AUTOSAR XML (schema 4-2-2)
package /STELLANTIS/EPT/ASWCs
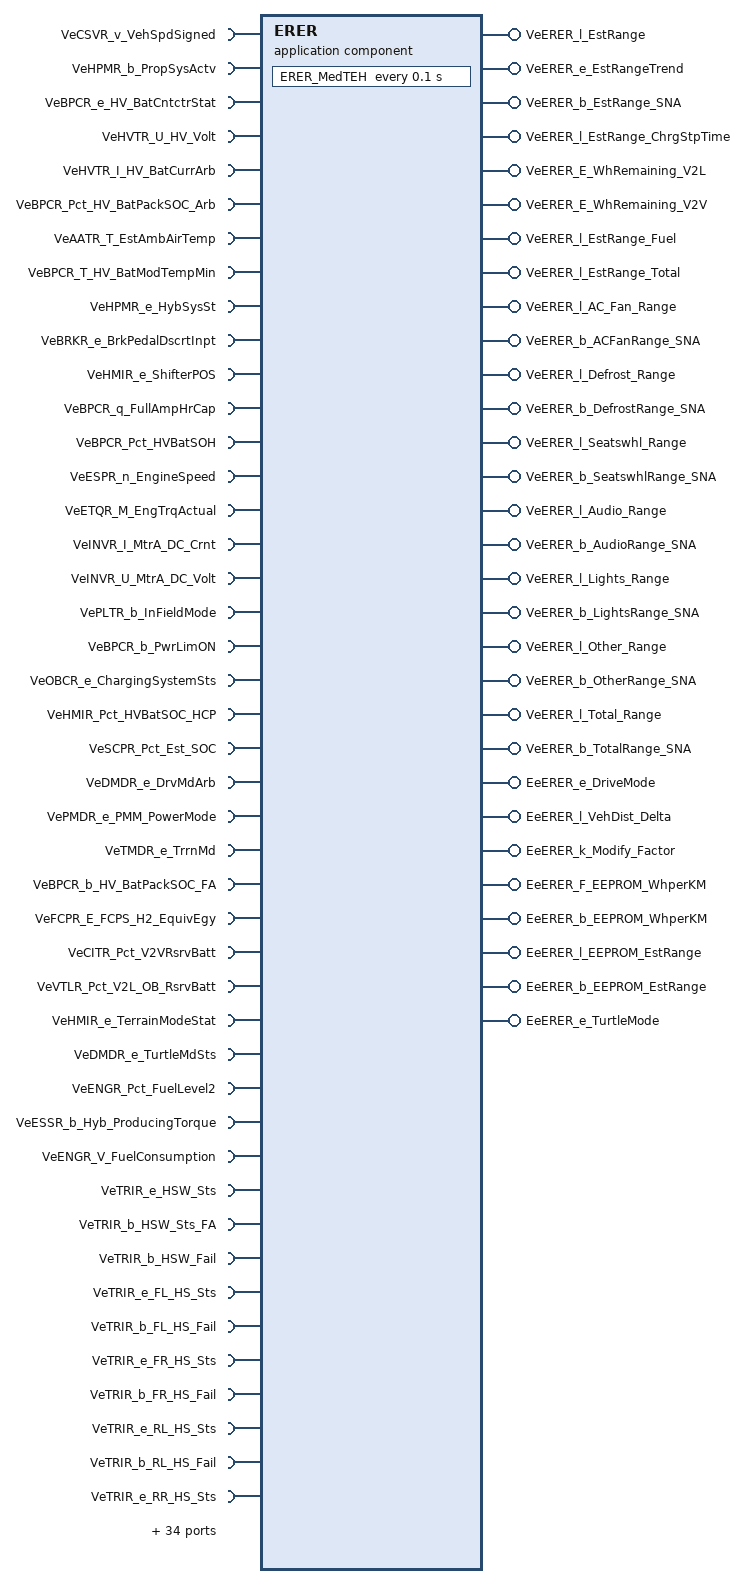
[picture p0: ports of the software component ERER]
  application sw component type ERER
    70 x require port:
      VeCSVR_v_VehSpdSigned: variation-point={short-label=vpVeCSVR_v_VehSpdSigned, sw-syscond=1}, nonqueued-receiver-com-spec{data-element=Value, init-value=0}, required-interface=VeCSVR_v_VehSpdSigned
      VeHPMR_b_PropSysActv: variation-point={short-label=vpVeHPMR_b_PropSysActv, sw-syscond=1}, nonqueued-receiver-com-spec{data-element=Value, init-value=0}, required-interface=VeHPMR_b_PropSysActv
      VeBPCR_e_HV_BatCntctrStat: variation-point={short-label=vpVeBPCR_e_HV_BatCntctrStat, sw-syscond=1}, nonqueued-receiver-com-spec{data-element=Value, init-value=CeHVTR_e_Open}, required-interface=VeBPCR_e_HV_BatCntctrStat
      VeHVTR_U_HV_Volt: variation-point={short-label=vpVeHVTR_U_HV_Volt, sw-syscond=1}, nonqueued-receiver-com-spec{data-element=Value, init-value=0}, required-interface=VeHVTR_U_HV_Volt
      VeHVTR_I_HV_BatCurrArb: variation-point={short-label=vpVeHVTR_I_HV_BatCurrArb, sw-syscond=1}, nonqueued-receiver-com-spec{data-element=Value, init-value=0}, required-interface=VeHVTR_I_HV_BatCurrArb
      VeBPCR_Pct_HV_BatPackSOC_Arb: variation-point={short-label=vpVeBPCR_Pct_HV_BatPackSOC_Arb, sw-syscond=1}, nonqueued-receiver-com-spec{data-element=Value, init-value=0}, required-interface=VeBPCR_Pct_HV_BatPackSOC_Arb
      VeAATR_T_EstAmbAirTemp: variation-point={short-label=vpVeAATR_T_EstAmbAirTemp, sw-syscond=1}, nonqueued-receiver-com-spec{data-element=Value, init-value=0}, required-interface=VeAATR_T_EstAmbAirTemp
      VeBPCR_T_HV_BatModTempMin: variation-point={short-label=vpVeBPCR_T_HV_BatModTempMin, sw-syscond=1}, nonqueued-receiver-com-spec{data-element=Value, init-value=0}, required-interface=VeBPCR_T_HV_BatModTempMin
      VeHPMR_e_HybSysSt: variation-point={short-label=vpVeHPMR_e_HybSysSt, sw-syscond=1}, nonqueued-receiver-com-spec{data-element=Value, init-value=CeHPMR_e_POWERUP}, required-interface=VeHPMR_e_HybSysSt
      VeBRKR_e_BrkPedalDscrtInpt: variation-point={short-label=vpVeBRKR_e_BrkPedalDscrtInpt, sw-syscond=1}, nonqueued-receiver-com-spec{data-element=Value, init-value=CeBRKR_e_BrkNotApplied}, required-interface=VeBRKR_e_BrkPedalDscrtInpt
      VeHMIR_e_ShifterPOS: variation-point={short-label=vpVeHMIR_e_ShifterPOS, sw-syscond=1}, nonqueued-receiver-com-spec{data-element=Value, init-value=CeHMIR_e_ShifterPosNoSelection}, required-interface=VeHMIR_e_ShifterPOS
      VeBPCR_q_FullAmpHrCap: variation-point={short-label=vpVeBPCR_q_FullAmpHrCap, sw-syscond=1}, nonqueued-receiver-com-spec{data-element=Value, init-value=0}, required-interface=VeBPCR_q_FullAmpHrCap
      VeBPCR_Pct_HVBatSOH: variation-point={short-label=vpVeBPCR_Pct_HVBatSOH, sw-syscond=1}, nonqueued-receiver-com-spec{data-element=Value, init-value=0}, required-interface=VeBPCR_Pct_HVBatSOH
      VeESPR_n_EngineSpeed: variation-point={short-label=vpVeESPR_n_EngineSpeed, sw-syscond=1}, nonqueued-receiver-com-spec{data-element=Value, init-value=0}, required-interface=VeESPR_n_EngineSpeed
      VeETQR_M_EngTrqActual: variation-point={short-label=vpVeETQR_M_EngTrqActual, sw-syscond=1}, nonqueued-receiver-com-spec{data-element=Value, init-value=0}, required-interface=VeETQR_M_EngTrqActual
      VeINVR_I_MtrA_DC_Crnt: variation-point={short-label=vpVeINVR_I_MtrA_DC_Crnt, sw-syscond=1}, nonqueued-receiver-com-spec{data-element=Value, init-value=0}, required-interface=VeINVR_I_MtrA_DC_Crnt
      VeINVR_U_MtrA_DC_Volt: variation-point={short-label=vpVeINVR_U_MtrA_DC_Volt, sw-syscond=1}, nonqueued-receiver-com-spec{data-element=Value, init-value=0}, required-interface=VeINVR_U_MtrA_DC_Volt
      VePLTR_b_InFieldMode: variation-point={short-label=vpVePLTR_b_InFieldMode, sw-syscond=1}, nonqueued-receiver-com-spec{data-element=Value, init-value=0}, required-interface=VePLTR_b_InFieldMode
      VeBPCR_b_PwrLimON: variation-point={short-label=vpVeBPCR_b_PwrLimON, sw-syscond=1}, nonqueued-receiver-com-spec{data-element=Value, init-value=0}, required-interface=VeBPCR_b_PwrLimON
      VeOBCR_e_ChargingSystemSts: variation-point={short-label=vpVeOBCR_e_ChargingSystemSts, sw-syscond=1}, nonqueued-receiver-com-spec{data-element=Value, init-value=CeOBCR_e_NotCharging}, required-interface=VeOBCR_e_ChargingSystemSts
      VeHMIR_Pct_HVBatSOC_HCP: variation-point={short-label=vpVeHMIR_Pct_HVBatSOC_HCP, sw-syscond=1}, nonqueued-receiver-com-spec{data-element=Value, init-value=0}, required-interface=VeHMIR_Pct_HVBatSOC_HCP
      VeSCPR_Pct_Est_SOC: variation-point={short-label=vpVeSCPR_Pct_Est_SOC, sw-syscond=1}, nonqueued-receiver-com-spec{data-element=Value, init-value=0}, required-interface=VeSCPR_Pct_Est_SOC
      VeDMDR_e_DrvMdArb: variation-point={short-label=vpVeDMDR_e_DrvMdArb, sw-syscond=1}, nonqueued-receiver-com-spec{data-element=Value, init-value=CeDMDR_e_NoDrvMd}, required-interface=VeDMDR_e_DrvMdArb
      VePMDR_e_PMM_PowerMode: variation-point={short-label=vpVePMDR_e_PMM_PowerMode, sw-syscond=1}, nonqueued-receiver-com-spec{data-element=Value, init-value=CePMDR_e_PowerMode_Off}, required-interface=VePMDR_e_PMM_PowerMode
      VeTMDR_e_TrrnMd: variation-point={short-label=vpVeTMDR_e_TrrnMd, sw-syscond=1}, nonqueued-receiver-com-spec{data-element=Value, init-value=CeTMDR_e_NotDefine}, required-interface=VeTMDR_e_TrrnMd
      VeBPCR_b_HV_BatPackSOC_FA: variation-point={short-label=vpVeBPCR_b_HV_BatPackSOC_FA, sw-syscond=1}, nonqueued-receiver-com-spec{data-element=Value, init-value=0}, required-interface=VeBPCR_b_HV_BatPackSOC_FA
      VeFCPR_E_FCPS_H2_EquivEgy: variation-point={short-label=vpVeFCPR_E_FCPS_H2_EquivEgy, sw-syscond=1}, nonqueued-receiver-com-spec{data-element=Value, init-value=0}, required-interface=VeFCPR_E_FCPS_H2_EquivEgy
      VeCITR_Pct_V2VRsrvBatt: variation-point={short-label=vpVeCITR_Pct_V2VRsrvBatt, sw-syscond=1}, nonqueued-receiver-com-spec{data-element=Value, init-value=0}, required-interface=VeCITR_Pct_V2VRsrvBatt
      VeVTLR_Pct_V2L_OB_RsrvBatt: variation-point={short-label=vpVeVTLR_Pct_V2L_OB_RsrvBatt, sw-syscond=1}, nonqueued-receiver-com-spec{data-element=Value, init-value=0}, required-interface=VeVTLR_Pct_V2L_OB_RsrvBatt
      VeHMIR_e_TerrainModeStat: variation-point={short-label=vpVeHMIR_e_TerrainModeStat, sw-syscond=1}, nonqueued-receiver-com-spec{data-element=Value, init-value=CeHMIR_e_AutoStat}, required-interface=VeHMIR_e_TerrainModeStat
      VeDMDR_e_TurtleMdSts: variation-point={short-label=vpVeDMDR_e_TurtleMdSts, sw-syscond=1}, nonqueued-receiver-com-spec{data-element=Value, init-value=CeDMDR_e_No_Turtle_Mode}, required-interface=VeDMDR_e_TurtleMdSts
      VeENGR_Pct_FuelLevel2: variation-point={short-label=vpVeENGR_Pct_FuelLevel2, sw-syscond=1}, nonqueued-receiver-com-spec{data-element=Value, init-value=0}, required-interface=VeENGR_Pct_FuelLevel2
      VeESSR_b_Hyb_ProducingTorque: variation-point={short-label=vpVeESSR_b_Hyb_ProducingTorque, sw-syscond=1}, nonqueued-receiver-com-spec{data-element=Value, init-value=0}, required-interface=VeESSR_b_Hyb_ProducingTorque
      VeENGR_V_FuelConsumption: variation-point={short-label=vpVeENGR_V_FuelConsumption, sw-syscond=1}, nonqueued-receiver-com-spec{data-element=Value, init-value=0}, required-interface=VeENGR_V_FuelConsumption
      VeTRIR_e_HSW_Sts: variation-point={short-label=vpVeTRIR_e_HSW_Sts, sw-syscond=1}, nonqueued-receiver-com-spec{data-element=Value, init-value=CeTRIR_e_ModeOFF}, required-interface=VeTRIR_e_HSW_Sts
      VeTRIR_b_HSW_Sts_FA: variation-point={short-label=vpVeTRIR_b_HSW_Sts_FA, sw-syscond=1}, nonqueued-receiver-com-spec{data-element=Value, init-value=0}, required-interface=VeTRIR_b_HSW_Sts_FA
      VeTRIR_b_HSW_Fail: variation-point={short-label=vpVeTRIR_b_HSW_Fail, sw-syscond=1}, nonqueued-receiver-com-spec{data-element=Value, init-value=0}, required-interface=VeTRIR_b_HSW_Fail
      VeTRIR_e_FL_HS_Sts: variation-point={short-label=vpVeTRIR_e_FL_HS_Sts, sw-syscond=1}, nonqueued-receiver-com-spec{data-element=Value, init-value=CeTRIR_e_ModeOFF}, required-interface=VeTRIR_e_FL_HS_Sts
      VeTRIR_b_FL_HS_Fail: variation-point={short-label=vpVeTRIR_b_FL_HS_Fail, sw-syscond=1}, nonqueued-receiver-com-spec{data-element=Value, init-value=0}, required-interface=VeTRIR_b_FL_HS_Fail
      VeTRIR_e_FR_HS_Sts: variation-point={short-label=vpVeTRIR_e_FR_HS_Sts, sw-syscond=1}, nonqueued-receiver-com-spec{data-element=Value, init-value=CeTRIR_e_ModeOFF}, required-interface=VeTRIR_e_FR_HS_Sts
      VeTRIR_b_FR_HS_Fail: variation-point={short-label=vpVeTRIR_b_FR_HS_Fail, sw-syscond=1}, nonqueued-receiver-com-spec{data-element=Value, init-value=0}, required-interface=VeTRIR_b_FR_HS_Fail
      VeTRIR_e_RL_HS_Sts: variation-point={short-label=vpVeTRIR_e_RL_HS_Sts, sw-syscond=1}, nonqueued-receiver-com-spec{data-element=Value, init-value=CeTRIR_e_ModeOFF}, required-interface=VeTRIR_e_RL_HS_Sts
      VeTRIR_b_RL_HS_Fail: variation-point={short-label=vpVeTRIR_b_RL_HS_Fail, sw-syscond=1}, nonqueued-receiver-com-spec{data-element=Value, init-value=0}, required-interface=VeTRIR_b_RL_HS_Fail
      VeTRIR_e_RR_HS_Sts: variation-point={short-label=vpVeTRIR_e_RR_HS_Sts, sw-syscond=1}, nonqueued-receiver-com-spec{data-element=Value, init-value=CeTRIR_e_ModeOFF}, required-interface=VeTRIR_e_RR_HS_Sts
      VeTRIR_b_RR_HS_Fail: variation-point={short-label=vpVeTRIR_b_RR_HS_Fail, sw-syscond=1}, nonqueued-receiver-com-spec{data-element=Value, init-value=0}, required-interface=VeTRIR_b_RR_HS_Fail
      VeTRIR_e_FL_VS_Sts: variation-point={short-label=vpVeTRIR_e_FL_VS_Sts, sw-syscond=1}, nonqueued-receiver-com-spec{data-element=Value, init-value=CeTRIR_e_ModeOFF}, required-interface=VeTRIR_e_FL_VS_Sts
      VeTRIR_b_FL_VS_Fail: variation-point={short-label=vpVeTRIR_b_FL_VS_Fail, sw-syscond=1}, nonqueued-receiver-com-spec{data-element=Value, init-value=0}, required-interface=VeTRIR_b_FL_VS_Fail
      VeTRIR_e_FR_VS_Sts: variation-point={short-label=vpVeTRIR_e_FR_VS_Sts, sw-syscond=1}, nonqueued-receiver-com-spec{data-element=Value, init-value=CeTRIR_e_ModeOFF}, required-interface=VeTRIR_e_FR_VS_Sts
      VeTRIR_b_FR_VS_Fail: variation-point={short-label=vpVeTRIR_b_FR_VS_Fail, sw-syscond=1}, nonqueued-receiver-com-spec{data-element=Value, init-value=0}, required-interface=VeTRIR_b_FR_VS_Fail
      VeTRIR_e_RL_VS_Sts: variation-point={short-label=vpVeTRIR_e_RL_VS_Sts, sw-syscond=1}, nonqueued-receiver-com-spec{data-element=Value, init-value=CeTRIR_e_ModeOFF}, required-interface=VeTRIR_e_RL_VS_Sts
      VeTRIR_b_RL_VS_Fail: variation-point={short-label=vpVeTRIR_b_RL_VS_Fail, sw-syscond=1}, nonqueued-receiver-com-spec{data-element=Value, init-value=0}, required-interface=VeTRIR_b_RL_VS_Fail
      VeTRIR_e_RR_VS_Sts: variation-point={short-label=vpVeTRIR_e_RR_VS_Sts, sw-syscond=1}, nonqueued-receiver-com-spec{data-element=Value, init-value=CeTRIR_e_ModeOFF}, required-interface=VeTRIR_e_RR_VS_Sts
      VeTRIR_b_RR_VS_Fail: variation-point={short-label=vpVeTRIR_b_RR_VS_Fail, sw-syscond=1}, nonqueued-receiver-com-spec{data-element=Value, init-value=0}, required-interface=VeTRIR_b_RR_VS_Fail
      VeHTRR_P_HVAC_HtrPwr: variation-point={short-label=vpVeHTRR_P_HVAC_HtrPwr, sw-syscond=1}, nonqueued-receiver-com-spec{data-element=Value, init-value=0}, required-interface=VeHTRR_P_HVAC_HtrPwr
      VeACCR_P_HVAC_CompPwrUsage: variation-point={short-label=vpVeACCR_P_HVAC_CompPwrUsage, sw-syscond=1}, nonqueued-receiver-com-spec{data-element=Value, init-value=0}, required-interface=VeACCR_P_HVAC_CompPwrUsage
      VeVTLR_P_InstantPwr_PPIM: variation-point={short-label=vpVeVTLR_P_InstantPwr_PPIM, sw-syscond=1}, nonqueued-receiver-com-spec{data-element=Value, init-value=0}, required-interface=VeVTLR_P_InstantPwr_PPIM
      VeVTLR_P_InstantPwr_IDCM: variation-point={short-label=vpVeVTLR_P_InstantPwr_IDCM, sw-syscond=1}, nonqueued-receiver-com-spec{data-element=Value, init-value=0}, required-interface=VeVTLR_P_InstantPwr_IDCM
      VePLTR_e_HiBmLvr_Stat: variation-point={short-label=vpVePLTR_e_HiBmLvr_Stat, sw-syscond=1}, nonqueued-receiver-com-spec{data-element=Value, init-value=CePLTR_e_HiBmLvr_Stat_Idle}, required-interface=VePLTR_e_HiBmLvr_Stat
      VePLTR_b_HiBmLvr_Stat_FA: variation-point={short-label=vpVePLTR_b_HiBmLvr_Stat_FA, sw-syscond=1}, nonqueued-receiver-com-spec{data-element=Value, init-value=0}, required-interface=VePLTR_b_HiBmLvr_Stat_FA
      VePLTR_b_RearFogLightSts: variation-point={short-label=vpVePLTR_b_RearFogLightSts, sw-syscond=1}, nonqueued-receiver-com-spec{data-element=Value, init-value=0}, required-interface=VePLTR_b_RearFogLightSts
      VePLTR_y_AUD_LVL: variation-point={short-label=vpVePLTR_y_AUD_LVL, sw-syscond=1}, nonqueued-receiver-com-spec{data-element=Value, init-value=0}, required-interface=VePLTR_y_AUD_LVL
      VePLTR_b_AUD_LVL_FA: variation-point={short-label=vpVePLTR_b_AUD_LVL_FA, sw-syscond=1}, nonqueued-receiver-com-spec{data-element=Value, init-value=0}, required-interface=VePLTR_b_AUD_LVL_FA
      VeTAIR_e_RearDefrostSts: variation-point={short-label=vpVeTAIR_e_RearDefrostSts, sw-syscond=1}, nonqueued-receiver-com-spec{data-element=Value, init-value=CeTAIR_e_RearDefrostSts_OFF}, required-interface=VeTAIR_e_RearDefrostSts
      VeTAIR_b_RearDefrostStsFA: variation-point={short-label=vpVeTAIR_b_RearDefrostStsFA, sw-syscond=1}, nonqueued-receiver-com-spec{data-element=Value, init-value=0}, required-interface=VeTAIR_b_RearDefrostStsFA
      VeTAIR_y_RearCabinFanSts: variation-point={short-label=vpVeTAIR_y_RearCabinFanSts, sw-syscond=1}, nonqueued-receiver-com-spec{data-element=Value, init-value=0}, required-interface=VeTAIR_y_RearCabinFanSts
      VeTAIR_b_RearCabinFanStsFA: variation-point={short-label=vpVeTAIR_b_RearCabinFanStsFA, sw-syscond=1}, nonqueued-receiver-com-spec{data-element=Value, init-value=0}, required-interface=VeTAIR_b_RearCabinFanStsFA
      VeIDCR_U_APM_LV_Voltage: variation-point={short-label=vpVeIDCR_U_APM_LV_Voltage, sw-syscond=1}, nonqueued-receiver-com-spec{data-element=Value, init-value=0}, required-interface=VeIDCR_U_APM_LV_Voltage
      VeIDCR_I_APM_LV_Current: variation-point={short-label=vpVeIDCR_I_APM_LV_Current, sw-syscond=1}, nonqueued-receiver-com-spec{data-element=Value, init-value=0}, required-interface=VeIDCR_I_APM_LV_Current
      VeTAIR_Pct_FrtBlwrCmd: variation-point={short-label=vpVeTAIR_Pct_FrtBlwrCmd, sw-syscond=1}, nonqueued-receiver-com-spec{data-element=Value, init-value=0}, required-interface=VeTAIR_Pct_FrtBlwrCmd
      VePRXR_b_CanNodeAMP: variation-point={short-label=vpVePRXR_b_CanNodeAMP, sw-syscond=1}, nonqueued-receiver-com-spec{data-element=Value, init-value=0}, required-interface=VePRXR_b_CanNodeAMP
    22 x provide port:
      VeERER_l_EstRange: nonqueued-sender-com-spec{data-element=Value, init-value=0}, provided-interface=VeERER_l_EstRange
      VeERER_e_EstRangeTrend: nonqueued-sender-com-spec{data-element=Value, init-value=CeERER_e_SNA}, provided-interface=VeERER_e_EstRangeTrend
      VeERER_b_EstRange_SNA: nonqueued-sender-com-spec{data-element=Value, init-value=0}, provided-interface=VeERER_b_EstRange_SNA
      VeERER_l_EstRange_ChrgStpTime: nonqueued-sender-com-spec{data-element=Value, init-value=0}, provided-interface=VeERER_l_EstRange_ChrgStpTime
      VeERER_E_WhRemaining_V2L: nonqueued-sender-com-spec{data-element=Value, init-value=0}, provided-interface=VeERER_E_WhRemaining_V2L
      VeERER_E_WhRemaining_V2V: nonqueued-sender-com-spec{data-element=Value, init-value=0}, provided-interface=VeERER_E_WhRemaining_V2V
      VeERER_l_EstRange_Fuel: nonqueued-sender-com-spec{data-element=Value, init-value=0}, provided-interface=VeERER_l_EstRange_Fuel
      VeERER_l_EstRange_Total: nonqueued-sender-com-spec{data-element=Value, init-value=0}, provided-interface=VeERER_l_EstRange_Total
      VeERER_l_AC_Fan_Range: nonqueued-sender-com-spec{data-element=Value, init-value=0}, provided-interface=VeERER_l_AC_Fan_Range
      VeERER_b_ACFanRange_SNA: nonqueued-sender-com-spec{data-element=Value, init-value=0}, provided-interface=VeERER_b_ACFanRange_SNA
      VeERER_l_Defrost_Range: nonqueued-sender-com-spec{data-element=Value, init-value=0}, provided-interface=VeERER_l_Defrost_Range
      VeERER_b_DefrostRange_SNA: nonqueued-sender-com-spec{data-element=Value, init-value=0}, provided-interface=VeERER_b_DefrostRange_SNA
      VeERER_l_Seatswhl_Range: nonqueued-sender-com-spec{data-element=Value, init-value=0}, provided-interface=VeERER_l_Seatswhl_Range
      VeERER_b_SeatswhlRange_SNA: nonqueued-sender-com-spec{data-element=Value, init-value=0}, provided-interface=VeERER_b_SeatswhlRange_SNA
      VeERER_l_Audio_Range: nonqueued-sender-com-spec{data-element=Value, init-value=0}, provided-interface=VeERER_l_Audio_Range
      VeERER_b_AudioRange_SNA: nonqueued-sender-com-spec{data-element=Value, init-value=0}, provided-interface=VeERER_b_AudioRange_SNA
      VeERER_l_Lights_Range: nonqueued-sender-com-spec{data-element=Value, init-value=0}, provided-interface=VeERER_l_Lights_Range
      VeERER_b_LightsRange_SNA: nonqueued-sender-com-spec{data-element=Value, init-value=0}, provided-interface=VeERER_b_LightsRange_SNA
      VeERER_l_Other_Range: nonqueued-sender-com-spec{data-element=Value, init-value=0}, provided-interface=VeERER_l_Other_Range
      VeERER_b_OtherRange_SNA: nonqueued-sender-com-spec{data-element=Value, init-value=0}, provided-interface=VeERER_b_OtherRange_SNA
      VeERER_l_Total_Range: nonqueued-sender-com-spec{data-element=Value, init-value=0}, provided-interface=VeERER_l_Total_Range
      VeERER_b_TotalRange_SNA: nonqueued-sender-com-spec{data-element=Value, init-value=0}, provided-interface=VeERER_b_TotalRange_SNA
    8 x require port:
      EeERER_e_DriveMode_Rx: nv-require-com-spec{init-value=0, variable=EeERER_e_DriveMode}, required-interface=EeERER_e_DriveMode
      EeERER_l_VehDist_Delta_Rx: nv-require-com-spec{init-value=0, variable=EeERER_l_VehDist_Delta}, required-interface=EeERER_l_VehDist_Delta
      EeERER_k_Modify_Factor_Rx: nv-require-com-spec{init-value=0, variable=EeERER_k_Modify_Factor}, required-interface=EeERER_k_Modify_Factor
      EeERER_F_EEPROM_WhperKM_Rx: nv-require-com-spec{init-value=0, variable=EeERER_F_EEPROM_WhperKM}, required-interface=EeERER_F_EEPROM_WhperKM
      EeERER_b_EEPROM_WhperKM_Rx: nv-require-com-spec{init-value=0, variable=EeERER_b_EEPROM_WhperKM}, required-interface=EeERER_b_EEPROM_WhperKM
      EeERER_l_EEPROM_EstRange_Rx: nv-require-com-spec{init-value=0, variable=EeERER_l_EEPROM_EstRange}, required-interface=EeERER_l_EEPROM_EstRange
      EeERER_b_EEPROM_EstRange_Rx: nv-require-com-spec{init-value=0, variable=EeERER_b_EEPROM_EstRange}, required-interface=EeERER_b_EEPROM_EstRange
      EeERER_e_TurtleMode_Rx: nv-require-com-spec{init-value=0, variable=EeERER_e_TurtleMode}, required-interface=EeERER_e_TurtleMode
    8 x provide port:
      EeERER_e_DriveMode: nv-provide-com-spec{ram-block-init-value=0, variable=EeERER_e_DriveMode}, provided-interface=EeERER_e_DriveMode
      EeERER_l_VehDist_Delta: nv-provide-com-spec{ram-block-init-value=0, variable=EeERER_l_VehDist_Delta}, provided-interface=EeERER_l_VehDist_Delta
      EeERER_k_Modify_Factor: nv-provide-com-spec{ram-block-init-value=0, variable=EeERER_k_Modify_Factor}, provided-interface=EeERER_k_Modify_Factor
      EeERER_F_EEPROM_WhperKM: nv-provide-com-spec{ram-block-init-value=0, variable=EeERER_F_EEPROM_WhperKM}, provided-interface=EeERER_F_EEPROM_WhperKM
      EeERER_b_EEPROM_WhperKM: nv-provide-com-spec{ram-block-init-value=0, variable=EeERER_b_EEPROM_WhperKM}, provided-interface=EeERER_b_EEPROM_WhperKM
      EeERER_l_EEPROM_EstRange: nv-provide-com-spec{ram-block-init-value=0, variable=EeERER_l_EEPROM_EstRange}, provided-interface=EeERER_l_EEPROM_EstRange
      EeERER_b_EEPROM_EstRange: nv-provide-com-spec{ram-block-init-value=0, variable=EeERER_b_EEPROM_EstRange}, provided-interface=EeERER_b_EEPROM_EstRange
      EeERER_e_TurtleMode: nv-provide-com-spec{ram-block-init-value=0, variable=EeERER_e_TurtleMode}, provided-interface=EeERER_e_TurtleMode
    behavior IB_ERER: data-type-mapping=msADTtoIDTMapping, handle-termination-and-restart=NO-SUPPORT
      timing event Event_MedTEH: start-on-event=ERER_MedTEH, period=0.1
      init event Event_ERER_ac_Init: start-on-event=ERER_ac_Init
      init event Event_PwrOn: start-on-event=ERER_PwrOn
      init event Event_PwrOff: start-on-event=ERER_PwrOff
      explicit-inter-runnable-variables:
        6 x data, all with category=VALUE, sw-calibration-access=READ-ONLY, init-value=0:
          VeERER_F_WHrpKm_EEPROM_Read_write_IRV: type=Float, variation-point={short-label=vpVeERER_F_WHrpKm_EEPROM_Read_write_IRV, sw-syscond=1}
          VeERER_l_EstRange_EEPROM_Read_write_IRV: type=Float, variation-point={short-label=vpVeERER_l_EstRange_EEPROM_Read_write_IRV, sw-syscond=1}
          VeERER_e_DriveMode_Wakeup_write_IRV: type=SInt16, variation-point={short-label=vpVeERER_e_DriveMode_Wakeup_write_IRV, sw-syscond=1}
          VeERER_k_Modify_Factor_Wakeup_write_IRV: type=Float, variation-point={short-label=vpVeERER_k_Modify_Factor_Wakeup_write_IRV, sw-syscond=1}
          VeERER_l_VehDist_Delta_Wakeup_write_IRV: type=Float, variation-point={short-label=vpVeERER_l_VehDist_Delta_Wakeup_write_IRV, sw-syscond=1}
          VeERER_e_TurtleMdSts_Wakeup_IRV: type=SInt16, variation-point={short-label=vpVeERER_e_TurtleMdSts_Wakeup_IRV, sw-syscond=1}
      4 x runnable:
        ERER_ac_Init
          data-send-points:
            access OUT_VeERER_e_EstRangeTrend_Value: accessed-variable=VeERER_e_EstRangeTrend.Value
          written-local-variables:
            6 x access:
              WV_VeERER_F_WHrpKm_EEPROM_Read_write_IRV: accessed-variable=VeERER_F_WHrpKm_EEPROM_Read_write_IRV, variation-point={short-label=vpWV_VeERER_F_WHrpKm_EEPROM_Read_write_IRV, sw-syscond=1}
              WV_VeERER_e_DriveMode_Wakeup_write_IRV: accessed-variable=VeERER_e_DriveMode_Wakeup_write_IRV, variation-point={short-label=vpWV_VeERER_e_DriveMode_Wakeup_write_IRV, sw-syscond=1}
              WV_VeERER_e_TurtleMdSts_Wakeup_IRV: accessed-variable=VeERER_e_TurtleMdSts_Wakeup_IRV, variation-point={short-label=vpWV_VeERER_e_TurtleMdSts_Wakeup_IRV, sw-syscond=1}
              WV_VeERER_k_Modify_Factor_Wakeup_write_IRV: accessed-variable=VeERER_k_Modify_Factor_Wakeup_write_IRV, variation-point={short-label=vpWV_VeERER_k_Modify_Factor_Wakeup_write_IRV, sw-syscond=1}
              WV_VeERER_l_EstRange_EEPROM_Read_write_IRV: accessed-variable=VeERER_l_EstRange_EEPROM_Read_write_IRV, variation-point={short-label=vpWV_VeERER_l_EstRange_EEPROM_Read_write_IRV, sw-syscond=1}
              WV_VeERER_l_VehDist_Delta_Wakeup_write_IRV: accessed-variable=VeERER_l_VehDist_Delta_Wakeup_write_IRV, variation-point={short-label=vpWV_VeERER_l_VehDist_Delta_Wakeup_write_IRV, sw-syscond=1}
        ERER_PwrOn
          data-receive-point-by-arguments:
            8 x access:
              IN_EeERER_F_EEPROM_WhperKM_Rx_EeERER_F_EEPROM_WhperKM: accessed-variable=EeERER_F_EEPROM_WhperKM_Rx.EeERER_F_EEPROM_WhperKM
              IN_EeERER_b_EEPROM_EstRange_Rx_EeERER_b_EEPROM_EstRange: accessed-variable=EeERER_b_EEPROM_EstRange_Rx.EeERER_b_EEPROM_EstRange
              IN_EeERER_b_EEPROM_WhperKM_Rx_EeERER_b_EEPROM_WhperKM: accessed-variable=EeERER_b_EEPROM_WhperKM_Rx.EeERER_b_EEPROM_WhperKM
              IN_EeERER_e_DriveMode_Rx_EeERER_e_DriveMode: accessed-variable=EeERER_e_DriveMode_Rx.EeERER_e_DriveMode
              IN_EeERER_e_TurtleMode_Rx_EeERER_e_TurtleMode: accessed-variable=EeERER_e_TurtleMode_Rx.EeERER_e_TurtleMode
              IN_EeERER_k_Modify_Factor_Rx_EeERER_k_Modify_Factor: accessed-variable=EeERER_k_Modify_Factor_Rx.EeERER_k_Modify_Factor
              IN_EeERER_l_EEPROM_EstRange_Rx_EeERER_l_EEPROM_EstRange: accessed-variable=EeERER_l_EEPROM_EstRange_Rx.EeERER_l_EEPROM_EstRange
              IN_EeERER_l_VehDist_Delta_Rx_EeERER_l_VehDist_Delta: accessed-variable=EeERER_l_VehDist_Delta_Rx.EeERER_l_VehDist_Delta
          data-send-points:
            22 x access:
              OUT_VeERER_l_EstRange_Total_Value: accessed-variable=VeERER_l_EstRange_Total.Value
              OUT_VeERER_e_EstRangeTrend_Value: accessed-variable=VeERER_e_EstRangeTrend.Value
              OUT_VeERER_b_EstRange_SNA_Value: accessed-variable=VeERER_b_EstRange_SNA.Value
              OUT_VeERER_l_EstRange_ChrgStpTime_Value: accessed-variable=VeERER_l_EstRange_ChrgStpTime.Value
              OUT_VeERER_E_WhRemaining_V2L_Value: accessed-variable=VeERER_E_WhRemaining_V2L.Value
              OUT_VeERER_E_WhRemaining_V2V_Value: accessed-variable=VeERER_E_WhRemaining_V2V.Value
              OUT_VeERER_l_EstRange_Value: accessed-variable=VeERER_l_EstRange.Value
              OUT_VeERER_l_EstRange_Fuel_Value: accessed-variable=VeERER_l_EstRange_Fuel.Value
              OUT_VeERER_l_AC_Fan_Range_Value: accessed-variable=VeERER_l_AC_Fan_Range.Value
              OUT_VeERER_b_ACFanRange_SNA_Value: accessed-variable=VeERER_b_ACFanRange_SNA.Value
              OUT_VeERER_l_Defrost_Range_Value: accessed-variable=VeERER_l_Defrost_Range.Value
              OUT_VeERER_b_DefrostRange_SNA_Value: accessed-variable=VeERER_b_DefrostRange_SNA.Value
              OUT_VeERER_l_Seatswhl_Range_Value: accessed-variable=VeERER_l_Seatswhl_Range.Value
              OUT_VeERER_b_SeatswhlRange_SNA_Value: accessed-variable=VeERER_b_SeatswhlRange_SNA.Value
              OUT_VeERER_l_Audio_Range_Value: accessed-variable=VeERER_l_Audio_Range.Value
              OUT_VeERER_b_AudioRange_SNA_Value: accessed-variable=VeERER_b_AudioRange_SNA.Value
              OUT_VeERER_l_Lights_Range_Value: accessed-variable=VeERER_l_Lights_Range.Value
              OUT_VeERER_b_LightsRange_SNA_Value: accessed-variable=VeERER_b_LightsRange_SNA.Value
              OUT_VeERER_l_Other_Range_Value: accessed-variable=VeERER_l_Other_Range.Value
              OUT_VeERER_b_OtherRange_SNA_Value: accessed-variable=VeERER_b_OtherRange_SNA.Value
              OUT_VeERER_l_Total_Range_Value: accessed-variable=VeERER_l_Total_Range.Value
              OUT_VeERER_b_TotalRange_SNA_Value: accessed-variable=VeERER_b_TotalRange_SNA.Value
          written-local-variables:
            6 x access:
              WV_VeERER_F_WHrpKm_EEPROM_Read_write_IRV: accessed-variable=VeERER_F_WHrpKm_EEPROM_Read_write_IRV, variation-point={short-label=vpWV_VeERER_F_WHrpKm_EEPROM_Read_write_IRV, sw-syscond=1}
              WV_VeERER_e_DriveMode_Wakeup_write_IRV: accessed-variable=VeERER_e_DriveMode_Wakeup_write_IRV, variation-point={short-label=vpWV_VeERER_e_DriveMode_Wakeup_write_IRV, sw-syscond=1}
              WV_VeERER_e_TurtleMdSts_Wakeup_IRV: accessed-variable=VeERER_e_TurtleMdSts_Wakeup_IRV, variation-point={short-label=vpWV_VeERER_e_TurtleMdSts_Wakeup_IRV, sw-syscond=1}
              WV_VeERER_k_Modify_Factor_Wakeup_write_IRV: accessed-variable=VeERER_k_Modify_Factor_Wakeup_write_IRV, variation-point={short-label=vpWV_VeERER_k_Modify_Factor_Wakeup_write_IRV, sw-syscond=1}
              WV_VeERER_l_EstRange_EEPROM_Read_write_IRV: accessed-variable=VeERER_l_EstRange_EEPROM_Read_write_IRV, variation-point={short-label=vpWV_VeERER_l_EstRange_EEPROM_Read_write_IRV, sw-syscond=1}
              WV_VeERER_l_VehDist_Delta_Wakeup_write_IRV: accessed-variable=VeERER_l_VehDist_Delta_Wakeup_write_IRV, variation-point={short-label=vpWV_VeERER_l_VehDist_Delta_Wakeup_write_IRV, sw-syscond=1}
        ERER_MedTEH: variation-point={short-label=vpERER_MedTEH, sw-syscond=1}
          data-receive-point-by-arguments:
            58 x access:
              IN_VeBPCR_Pct_HVBatSOH_Value: accessed-variable=VeBPCR_Pct_HVBatSOH.Value, variation-point={short-label=vpIN_VeBPCR_Pct_HVBatSOH_Value, sw-syscond=1}
              IN_VeBPCR_Pct_HV_BatPackSOC_Arb_Value: accessed-variable=VeBPCR_Pct_HV_BatPackSOC_Arb.Value, variation-point={short-label=vpIN_VeBPCR_Pct_HV_BatPackSOC_Arb_Value, sw-syscond=1}
              IN_VeBPCR_T_HV_BatModTempMin_Value: accessed-variable=VeBPCR_T_HV_BatModTempMin.Value, variation-point={short-label=vpIN_VeBPCR_T_HV_BatModTempMin_Value, sw-syscond=1}
              IN_VeBPCR_b_HV_BatPackSOC_FA_Value: accessed-variable=VeBPCR_b_HV_BatPackSOC_FA.Value, variation-point={short-label=vpIN_VeBPCR_b_HV_BatPackSOC_FA_Value, sw-syscond=1}
              IN_VeBPCR_b_PwrLimON_Value: accessed-variable=VeBPCR_b_PwrLimON.Value, variation-point={short-label=vpIN_VeBPCR_b_PwrLimON_Value, sw-syscond=1}
              IN_VeBPCR_e_HV_BatCntctrStat_Value: accessed-variable=VeBPCR_e_HV_BatCntctrStat.Value, variation-point={short-label=vpIN_VeBPCR_e_HV_BatCntctrStat_Value, sw-syscond=1}
              IN_VeBPCR_q_FullAmpHrCap_Value: accessed-variable=VeBPCR_q_FullAmpHrCap.Value, variation-point={short-label=vpIN_VeBPCR_q_FullAmpHrCap_Value, sw-syscond=1}
              IN_VeBRKR_e_BrkPedalDscrtInpt_Value: accessed-variable=VeBRKR_e_BrkPedalDscrtInpt.Value, variation-point={short-label=vpIN_VeBRKR_e_BrkPedalDscrtInpt_Value, sw-syscond=1}
              IN_VeCITR_Pct_V2VRsrvBatt_Value: accessed-variable=VeCITR_Pct_V2VRsrvBatt.Value, variation-point={short-label=vpIN_VeCITR_Pct_V2VRsrvBatt_Value, sw-syscond=1}
              IN_VeCSVR_v_VehSpdSigned_Value: accessed-variable=VeCSVR_v_VehSpdSigned.Value, variation-point={short-label=vpIN_VeCSVR_v_VehSpdSigned_Value, sw-syscond=1}
              IN_VeDMDR_e_DrvMdArb_Value: accessed-variable=VeDMDR_e_DrvMdArb.Value, variation-point={short-label=vpIN_VeDMDR_e_DrvMdArb_Value, sw-syscond=1}
              IN_VeDMDR_e_TurtleMdSts_Value: accessed-variable=VeDMDR_e_TurtleMdSts.Value, variation-point={short-label=vpIN_VeDMDR_e_TurtleMdSts_Value, sw-syscond=1}
              IN_VeENGR_Pct_FuelLevel2_Value: accessed-variable=VeENGR_Pct_FuelLevel2.Value, variation-point={short-label=vpIN_VeENGR_Pct_FuelLevel2_Value, sw-syscond=1}
              IN_VeENGR_V_FuelConsumption_Value: accessed-variable=VeENGR_V_FuelConsumption.Value, variation-point={short-label=vpIN_VeENGR_V_FuelConsumption_Value, sw-syscond=1}
              IN_VeESPR_n_EngineSpeed_Value: accessed-variable=VeESPR_n_EngineSpeed.Value, variation-point={short-label=vpIN_VeESPR_n_EngineSpeed_Value, sw-syscond=1}
              IN_VeESSR_b_Hyb_ProducingTorque_Value: accessed-variable=VeESSR_b_Hyb_ProducingTorque.Value, variation-point={short-label=vpIN_VeESSR_b_Hyb_ProducingTorque_Value, sw-syscond=1}
              IN_VeETQR_M_EngTrqActual_Value: accessed-variable=VeETQR_M_EngTrqActual.Value, variation-point={short-label=vpIN_VeETQR_M_EngTrqActual_Value, sw-syscond=1}
              IN_VeFCPR_E_FCPS_H2_EquivEgy_Value: accessed-variable=VeFCPR_E_FCPS_H2_EquivEgy.Value, variation-point={short-label=vpIN_VeFCPR_E_FCPS_H2_EquivEgy_Value, sw-syscond=1}
              IN_VeHMIR_Pct_HVBatSOC_HCP_Value: accessed-variable=VeHMIR_Pct_HVBatSOC_HCP.Value, variation-point={short-label=vpIN_VeHMIR_Pct_HVBatSOC_HCP_Value, sw-syscond=1}
              IN_VeHMIR_e_ShifterPOS_Value: accessed-variable=VeHMIR_e_ShifterPOS.Value, variation-point={short-label=vpIN_VeHMIR_e_ShifterPOS_Value, sw-syscond=1}
              IN_VeHMIR_e_TerrainModeStat_Value: accessed-variable=VeHMIR_e_TerrainModeStat.Value, variation-point={short-label=vpIN_VeHMIR_e_TerrainModeStat_Value, sw-syscond=1}
              IN_VeHPMR_b_PropSysActv_Value: accessed-variable=VeHPMR_b_PropSysActv.Value, variation-point={short-label=vpIN_VeHPMR_b_PropSysActv_Value, sw-syscond=1}
              IN_VeHPMR_e_HybSysSt_Value: accessed-variable=VeHPMR_e_HybSysSt.Value, variation-point={short-label=vpIN_VeHPMR_e_HybSysSt_Value, sw-syscond=1}
              IN_VeHVTR_I_HV_BatCurrArb_Value: accessed-variable=VeHVTR_I_HV_BatCurrArb.Value, variation-point={short-label=vpIN_VeHVTR_I_HV_BatCurrArb_Value, sw-syscond=1}
              IN_VeHVTR_U_HV_Volt_Value: accessed-variable=VeHVTR_U_HV_Volt.Value, variation-point={short-label=vpIN_VeHVTR_U_HV_Volt_Value, sw-syscond=1}
              IN_VeIDCR_I_APM_LV_Current_Value: accessed-variable=VeIDCR_I_APM_LV_Current.Value, variation-point={short-label=vpIN_VeIDCR_I_APM_LV_Current_Value, sw-syscond=1}
              IN_VeIDCR_U_APM_LV_Voltage_Value: accessed-variable=VeIDCR_U_APM_LV_Voltage.Value, variation-point={short-label=vpIN_VeIDCR_U_APM_LV_Voltage_Value, sw-syscond=1}
              IN_VeINVR_I_MtrA_DC_Crnt_Value: accessed-variable=VeINVR_I_MtrA_DC_Crnt.Value, variation-point={short-label=vpIN_VeINVR_I_MtrA_DC_Crnt_Value, sw-syscond=1}
              IN_VeINVR_U_MtrA_DC_Volt_Value: accessed-variable=VeINVR_U_MtrA_DC_Volt.Value, variation-point={short-label=vpIN_VeINVR_U_MtrA_DC_Volt_Value, sw-syscond=1}
              IN_VeOBCR_e_ChargingSystemSts_Value: accessed-variable=VeOBCR_e_ChargingSystemSts.Value, variation-point={short-label=vpIN_VeOBCR_e_ChargingSystemSts_Value, sw-syscond=1}
              IN_VePLTR_b_AUD_LVL_FA_Value: accessed-variable=VePLTR_b_AUD_LVL_FA.Value, variation-point={short-label=vpIN_VePLTR_b_AUD_LVL_FA_Value, sw-syscond=1}
              IN_VePLTR_b_InFieldMode_Value: accessed-variable=VePLTR_b_InFieldMode.Value, variation-point={short-label=vpIN_VePLTR_b_InFieldMode_Value, sw-syscond=1}
              IN_VePLTR_b_RearFogLightSts_Value: accessed-variable=VePLTR_b_RearFogLightSts.Value, variation-point={short-label=vpIN_VePLTR_b_RearFogLightSts_Value, sw-syscond=1}
              IN_VePLTR_e_HiBmLvr_Stat_Value: accessed-variable=VePLTR_e_HiBmLvr_Stat.Value, variation-point={short-label=vpIN_VePLTR_e_HiBmLvr_Stat_Value, sw-syscond=1}
              IN_VePMDR_e_PMM_PowerMode_Value: accessed-variable=VePMDR_e_PMM_PowerMode.Value, variation-point={short-label=vpIN_VePMDR_e_PMM_PowerMode_Value, sw-syscond=1}
              IN_VePRXR_b_CanNodeAMP_Value: accessed-variable=VePRXR_b_CanNodeAMP.Value, variation-point={short-label=vpIN_VePRXR_b_CanNodeAMP_Value, sw-syscond=1}
              IN_VeSCPR_Pct_Est_SOC_Value: accessed-variable=VeSCPR_Pct_Est_SOC.Value, variation-point={short-label=vpIN_VeSCPR_Pct_Est_SOC_Value, sw-syscond=1}
              IN_VeTAIR_b_RearCabinFanStsFA_Value: accessed-variable=VeTAIR_b_RearCabinFanStsFA.Value, variation-point={short-label=vpIN_VeTAIR_b_RearCabinFanStsFA_Value, sw-syscond=1}
              IN_VeTAIR_e_RearDefrostSts_Value: accessed-variable=VeTAIR_e_RearDefrostSts.Value, variation-point={short-label=vpIN_VeTAIR_e_RearDefrostSts_Value, sw-syscond=1}
              IN_VeTRIR_b_FL_HS_Fail_Value: accessed-variable=VeTRIR_b_FL_HS_Fail.Value, variation-point={short-label=vpIN_VeTRIR_b_FL_HS_Fail_Value, sw-syscond=1}
              IN_VeTRIR_b_FL_VS_Fail_Value: accessed-variable=VeTRIR_b_FL_VS_Fail.Value, variation-point={short-label=vpIN_VeTRIR_b_FL_VS_Fail_Value, sw-syscond=1}
              IN_VeTRIR_b_FR_HS_Fail_Value: accessed-variable=VeTRIR_b_FR_HS_Fail.Value, variation-point={short-label=vpIN_VeTRIR_b_FR_HS_Fail_Value, sw-syscond=1}
              IN_VeTRIR_b_FR_VS_Fail_Value: accessed-variable=VeTRIR_b_FR_VS_Fail.Value, variation-point={short-label=vpIN_VeTRIR_b_FR_VS_Fail_Value, sw-syscond=1}
              IN_VeTRIR_b_HSW_Fail_Value: accessed-variable=VeTRIR_b_HSW_Fail.Value, variation-point={short-label=vpIN_VeTRIR_b_HSW_Fail_Value, sw-syscond=1}
              IN_VeTRIR_b_RL_HS_Fail_Value: accessed-variable=VeTRIR_b_RL_HS_Fail.Value, variation-point={short-label=vpIN_VeTRIR_b_RL_HS_Fail_Value, sw-syscond=1}
              IN_VeTRIR_b_RL_VS_Fail_Value: accessed-variable=VeTRIR_b_RL_VS_Fail.Value, variation-point={short-label=vpIN_VeTRIR_b_RL_VS_Fail_Value, sw-syscond=1}
              IN_VeTRIR_b_RR_HS_Fail_Value: accessed-variable=VeTRIR_b_RR_HS_Fail.Value, variation-point={short-label=vpIN_VeTRIR_b_RR_HS_Fail_Value, sw-syscond=1}
              IN_VeTRIR_b_RR_VS_Fail_Value: accessed-variable=VeTRIR_b_RR_VS_Fail.Value, variation-point={short-label=vpIN_VeTRIR_b_RR_VS_Fail_Value, sw-syscond=1}
              IN_VeTRIR_e_FL_HS_Sts_Value: accessed-variable=VeTRIR_e_FL_HS_Sts.Value, variation-point={short-label=vpIN_VeTRIR_e_FL_HS_Sts_Value, sw-syscond=1}
              IN_VeTRIR_e_FL_VS_Sts_Value: accessed-variable=VeTRIR_e_FL_VS_Sts.Value, variation-point={short-label=vpIN_VeTRIR_e_FL_VS_Sts_Value, sw-syscond=1}
              IN_VeTRIR_e_FR_HS_Sts_Value: accessed-variable=VeTRIR_e_FR_HS_Sts.Value, variation-point={short-label=vpIN_VeTRIR_e_FR_HS_Sts_Value, sw-syscond=1}
              IN_VeTRIR_e_FR_VS_Sts_Value: accessed-variable=VeTRIR_e_FR_VS_Sts.Value, variation-point={short-label=vpIN_VeTRIR_e_FR_VS_Sts_Value, sw-syscond=1}
              IN_VeTRIR_e_HSW_Sts_Value: accessed-variable=VeTRIR_e_HSW_Sts.Value, variation-point={short-label=vpIN_VeTRIR_e_HSW_Sts_Value, sw-syscond=1}
              IN_VeTRIR_e_RL_HS_Sts_Value: accessed-variable=VeTRIR_e_RL_HS_Sts.Value, variation-point={short-label=vpIN_VeTRIR_e_RL_HS_Sts_Value, sw-syscond=1}
              IN_VeTRIR_e_RL_VS_Sts_Value: accessed-variable=VeTRIR_e_RL_VS_Sts.Value, variation-point={short-label=vpIN_VeTRIR_e_RL_VS_Sts_Value, sw-syscond=1}
              IN_VeTRIR_e_RR_HS_Sts_Value: accessed-variable=VeTRIR_e_RR_HS_Sts.Value, variation-point={short-label=vpIN_VeTRIR_e_RR_HS_Sts_Value, sw-syscond=1}
              IN_VeTRIR_e_RR_VS_Sts_Value: accessed-variable=VeTRIR_e_RR_VS_Sts.Value, variation-point={short-label=vpIN_VeTRIR_e_RR_VS_Sts_Value, sw-syscond=1}
              IN_VeVTLR_Pct_V2L_OB_RsrvBatt_Value: accessed-variable=VeVTLR_Pct_V2L_OB_RsrvBatt.Value, variation-point={short-label=vpIN_VeVTLR_Pct_V2L_OB_RsrvBatt_Value, sw-syscond=1}
          data-send-points:
            22 x access:
              OUT_VeERER_l_EstRange_Value: accessed-variable=VeERER_l_EstRange.Value
              OUT_VeERER_e_EstRangeTrend_Value: accessed-variable=VeERER_e_EstRangeTrend.Value
              OUT_VeERER_b_EstRange_SNA_Value: accessed-variable=VeERER_b_EstRange_SNA.Value
              OUT_VeERER_l_EstRange_ChrgStpTime_Value: accessed-variable=VeERER_l_EstRange_ChrgStpTime.Value
              OUT_VeERER_E_WhRemaining_V2L_Value: accessed-variable=VeERER_E_WhRemaining_V2L.Value
              OUT_VeERER_E_WhRemaining_V2V_Value: accessed-variable=VeERER_E_WhRemaining_V2V.Value
              OUT_VeERER_l_EstRange_Fuel_Value: accessed-variable=VeERER_l_EstRange_Fuel.Value
              OUT_VeERER_l_EstRange_Total_Value: accessed-variable=VeERER_l_EstRange_Total.Value
              OUT_VeERER_l_AC_Fan_Range_Value: accessed-variable=VeERER_l_AC_Fan_Range.Value
              OUT_VeERER_b_ACFanRange_SNA_Value: accessed-variable=VeERER_b_ACFanRange_SNA.Value
              OUT_VeERER_l_Defrost_Range_Value: accessed-variable=VeERER_l_Defrost_Range.Value
              OUT_VeERER_b_DefrostRange_SNA_Value: accessed-variable=VeERER_b_DefrostRange_SNA.Value
              OUT_VeERER_l_Seatswhl_Range_Value: accessed-variable=VeERER_l_Seatswhl_Range.Value
              OUT_VeERER_b_SeatswhlRange_SNA_Value: accessed-variable=VeERER_b_SeatswhlRange_SNA.Value
              OUT_VeERER_l_Audio_Range_Value: accessed-variable=VeERER_l_Audio_Range.Value
              OUT_VeERER_b_AudioRange_SNA_Value: accessed-variable=VeERER_b_AudioRange_SNA.Value
              OUT_VeERER_l_Lights_Range_Value: accessed-variable=VeERER_l_Lights_Range.Value
              OUT_VeERER_b_LightsRange_SNA_Value: accessed-variable=VeERER_b_LightsRange_SNA.Value
              OUT_VeERER_l_Other_Range_Value: accessed-variable=VeERER_l_Other_Range.Value
              OUT_VeERER_b_OtherRange_SNA_Value: accessed-variable=VeERER_b_OtherRange_SNA.Value
              OUT_VeERER_l_Total_Range_Value: accessed-variable=VeERER_l_Total_Range.Value
              OUT_VeERER_b_TotalRange_SNA_Value: accessed-variable=VeERER_b_TotalRange_SNA.Value
          read-local-variables:
            6 x access:
              RV_VeERER_F_WHrpKm_EEPROM_Read_write_IRV: accessed-variable=VeERER_F_WHrpKm_EEPROM_Read_write_IRV, variation-point={short-label=vpRV_VeERER_F_WHrpKm_EEPROM_Read_write_IRV, sw-syscond=1}
              RV_VeERER_e_DriveMode_Wakeup_write_IRV: accessed-variable=VeERER_e_DriveMode_Wakeup_write_IRV, variation-point={short-label=vpRV_VeERER_e_DriveMode_Wakeup_write_IRV, sw-syscond=1}
              RV_VeERER_e_TurtleMdSts_Wakeup_IRV: accessed-variable=VeERER_e_TurtleMdSts_Wakeup_IRV, variation-point={short-label=vpRV_VeERER_e_TurtleMdSts_Wakeup_IRV, sw-syscond=1}
              RV_VeERER_k_Modify_Factor_Wakeup_write_IRV: accessed-variable=VeERER_k_Modify_Factor_Wakeup_write_IRV, variation-point={short-label=vpRV_VeERER_k_Modify_Factor_Wakeup_write_IRV, sw-syscond=1}
              RV_VeERER_l_EstRange_EEPROM_Read_write_IRV: accessed-variable=VeERER_l_EstRange_EEPROM_Read_write_IRV, variation-point={short-label=vpRV_VeERER_l_EstRange_EEPROM_Read_write_IRV, sw-syscond=1}
              RV_VeERER_l_VehDist_Delta_Wakeup_write_IRV: accessed-variable=VeERER_l_VehDist_Delta_Wakeup_write_IRV, variation-point={short-label=vpRV_VeERER_l_VehDist_Delta_Wakeup_write_IRV, sw-syscond=1}
        ERER_PwrOff
          data-send-points:
            8 x access:
              OUT_EeERER_e_DriveMode_EeERER_e_DriveMode: accessed-variable=EeERER_e_DriveMode.EeERER_e_DriveMode
              OUT_EeERER_l_VehDist_Delta_EeERER_l_VehDist_Delta: accessed-variable=EeERER_l_VehDist_Delta.EeERER_l_VehDist_Delta
              OUT_EeERER_k_Modify_Factor_EeERER_k_Modify_Factor: accessed-variable=EeERER_k_Modify_Factor.EeERER_k_Modify_Factor
              OUT_EeERER_F_EEPROM_WhperKM_EeERER_F_EEPROM_WhperKM: accessed-variable=EeERER_F_EEPROM_WhperKM.EeERER_F_EEPROM_WhperKM
              OUT_EeERER_b_EEPROM_WhperKM_EeERER_b_EEPROM_WhperKM: accessed-variable=EeERER_b_EEPROM_WhperKM.EeERER_b_EEPROM_WhperKM
              OUT_EeERER_l_EEPROM_EstRange_EeERER_l_EEPROM_EstRange: accessed-variable=EeERER_l_EEPROM_EstRange.EeERER_l_EEPROM_EstRange
              OUT_EeERER_b_EEPROM_EstRange_EeERER_b_EEPROM_EstRange: accessed-variable=EeERER_b_EEPROM_EstRange.EeERER_b_EEPROM_EstRange
              OUT_EeERER_e_TurtleMode_EeERER_e_TurtleMode: accessed-variable=EeERER_e_TurtleMode.EeERER_e_TurtleMode
      variation point proxy Variant_ERER_1: category=CONDITION, condition-access=1
